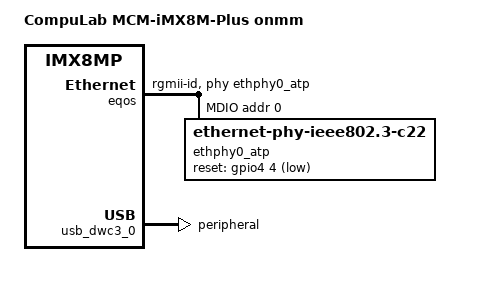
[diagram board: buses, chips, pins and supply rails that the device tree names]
/ {
	model = "CompuLab MCM-iMX8M-Plus onmm";
	compatible = "compulab,mcm-imx8m-plus", "fsl,imx8mp";
};

&iomuxc {

	pinctrl_eqos_atp: eqosgrpatp {
		fsl,pins = <
			MX8MP_IOMUXC_ENET_MDC__ENET_QOS_MDC				0x2
			MX8MP_IOMUXC_ENET_MDIO__ENET_QOS_MDIO				0x2
			MX8MP_IOMUXC_ENET_RD0__ENET_QOS_RGMII_RD0			0x90
			MX8MP_IOMUXC_ENET_RD1__ENET_QOS_RGMII_RD1			0x90
			MX8MP_IOMUXC_ENET_RD2__ENET_QOS_RGMII_RD2			0x90
			MX8MP_IOMUXC_ENET_RD3__ENET_QOS_RGMII_RD3			0x90
			MX8MP_IOMUXC_ENET_RXC__CCM_ENET_QOS_CLOCK_GENERATE_RX_CLK	0x90
			MX8MP_IOMUXC_ENET_RX_CTL__ENET_QOS_RGMII_RX_CTL			0x90
			MX8MP_IOMUXC_ENET_TD0__ENET_QOS_RGMII_TD0			0x16
			MX8MP_IOMUXC_ENET_TD1__ENET_QOS_RGMII_TD1			0x16
			MX8MP_IOMUXC_ENET_TD2__ENET_QOS_RGMII_TD2			0x16
			MX8MP_IOMUXC_ENET_TD3__ENET_QOS_RGMII_TD3			0x16
			MX8MP_IOMUXC_ENET_TX_CTL__ENET_QOS_RGMII_TX_CTL			0x16
			MX8MP_IOMUXC_ENET_TXC__CCM_ENET_QOS_CLOCK_GENERATE_TX_CLK	0x16
			MX8MP_IOMUXC_SAI1_RXD2__GPIO4_IO04				0x10
		>;
	};
};

&eqos {
	pinctrl-names = "default";
	pinctrl-0 = <&pinctrl_eqos_atp>;
	phy-mode = "rgmii-id";
	phy-handle = <&ethphy0_atp>;
	snps,force_thresh_dma_mode;
	snps,mtl-tx-config = <&mtl_tx_setup>;
	snps,mtl-rx-config = <&mtl_rx_setup>;
	status = "okay";

	mdio {
		compatible = "snps,dwmac-mdio";
		#address-cells = <1>;
		#size-cells = <0>;

		ethphy0_atp: ethernet-phy@0 {
			compatible = "ethernet-phy-ieee802.3-c22";
			reg = <0>;
			eee-broken-1000t;
			reset-gpios = <&gpio4 4 GPIO_ACTIVE_LOW>;
			reset-assert-us = <15000>;
			reset-deassert-us = <100000>;
			realtek,clkout-disable;
		};
	};
};

&fec {
	status = "disabled";
};

&usb_dwc3_0 {
	dr_mode = "peripheral";
};
